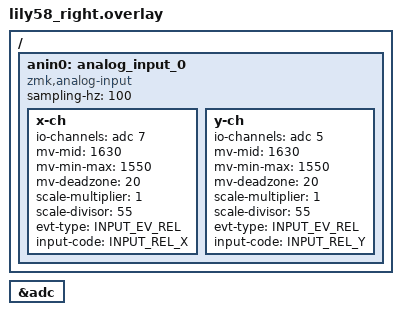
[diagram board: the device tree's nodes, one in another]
#include <zephyr/dt-bindings/input/input-event-codes.h>

&adc {
    status = "okay";
};

/ {
    anin0: analog_input_0 {
        compatible = "zmk,analog-input";
        sampling-hz = <100>;

        x-ch {
            io-channels = <&adc 7>;        // AIN7 -> P0.31
            mv-mid = <1630>;
            mv-min-max = <1550>;
            mv-deadzone = <20>;
            scale-multiplier = <1>;
            scale-divisor = <55>;
            // invert;                     // Uncomment if X is backwards
            evt-type = <INPUT_EV_REL>;
            input-code = <INPUT_REL_X>;
        };

        y-ch {
            io-channels = <&adc 5>;        // AIN5 -> P0.29
            mv-mid = <1630>;
            mv-min-max = <1550>;
            mv-deadzone = <20>;
            scale-multiplier = <1>;
            scale-divisor = <55>;
            // invert;                     // Uncomment if Y is backwards
            evt-type = <INPUT_EV_REL>;
            input-code = <INPUT_REL_Y>;
        };
    };
};
